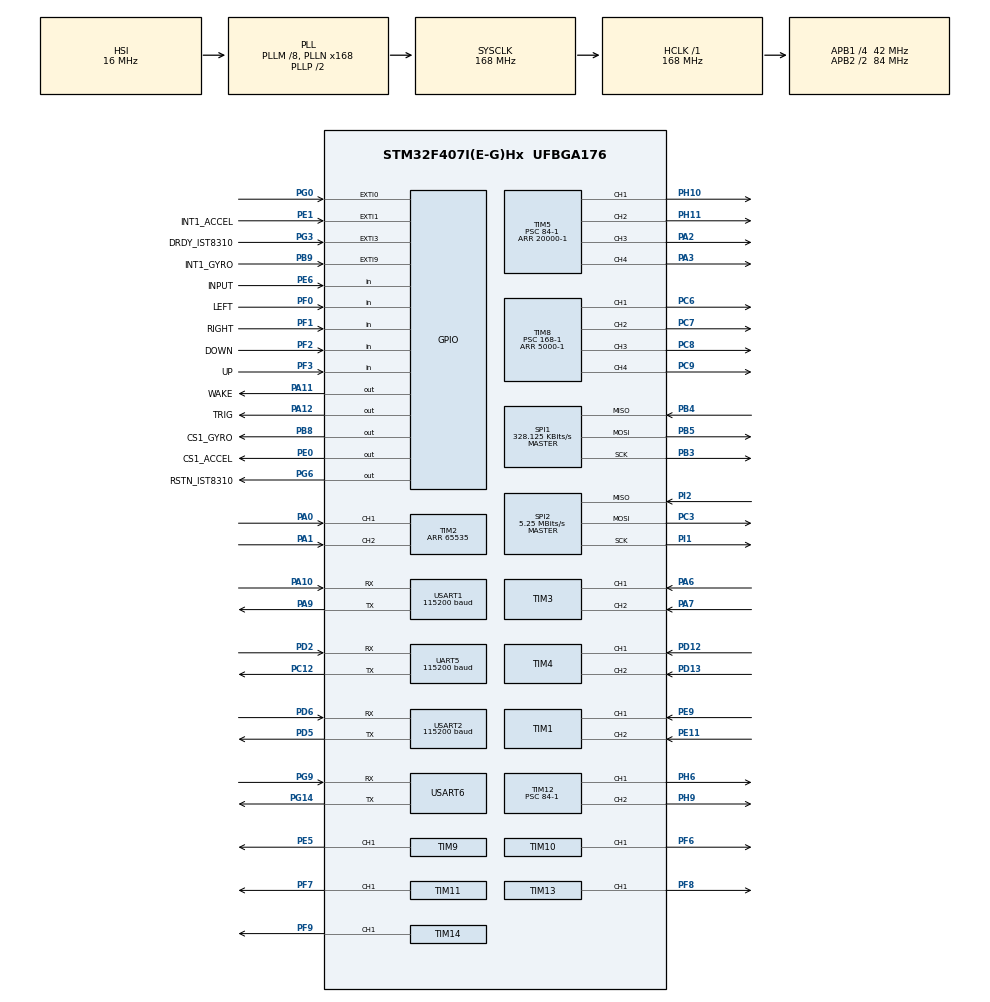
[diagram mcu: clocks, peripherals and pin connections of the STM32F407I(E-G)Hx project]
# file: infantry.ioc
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Dma.Request0=USART1_RX
Dma.Request1=USART6_RX
Dma.Request2=USART6_TX
Dma.Request3=SPI2_TX
Dma.Request4=UART5_TX
Dma.Request5=USART2_RX
Dma.Request6=UART5_RX
Dma.SPI2_TX.3.Direction=DMA_MEMORY_TO_PERIPH
Dma.SPI2_TX.3.FIFOMode=DMA_FIFOMODE_DISABLE
Dma.SPI2_TX.3.Instance=DMA1_Stream4
Dma.SPI2_TX.3.MemDataAlignment=DMA_MDATAALIGN_BYTE
Dma.SPI2_TX.3.MemInc=DMA_MINC_ENABLE
Dma.SPI2_TX.3.Mode=DMA_NORMAL
Dma.SPI2_TX.3.PeriphDataAlignment=DMA_PDATAALIGN_BYTE
Dma.SPI2_TX.3.PeriphInc=DMA_PINC_DISABLE
Dma.SPI2_TX.3.Priority=DMA_PRIORITY_MEDIUM
Dma.UART5_RX.6.Direction=DMA_PERIPH_TO_MEMORY
Dma.UART5_RX.6.FIFOMode=DMA_FIFOMODE_DISABLE
Dma.UART5_RX.6.Instance=DMA1_Stream0
Dma.UART5_RX.6.MemDataAlignment=DMA_MDATAALIGN_BYTE
Dma.UART5_RX.6.MemInc=DMA_MINC_ENABLE
Dma.UART5_RX.6.Mode=DMA_NORMAL
Dma.UART5_RX.6.PeriphDataAlignment=DMA_PDATAALIGN_BYTE
Dma.UART5_RX.6.PeriphInc=DMA_PINC_DISABLE
Dma.UART5_RX.6.Priority=DMA_PRIORITY_HIGH
Dma.UART5_TX.4.Direction=DMA_MEMORY_TO_PERIPH
Dma.UART5_TX.4.FIFOMode=DMA_FIFOMODE_DISABLE
Dma.UART5_TX.4.Instance=DMA1_Stream7
Dma.UART5_TX.4.MemDataAlignment=DMA_MDATAALIGN_BYTE
Dma.UART5_TX.4.MemInc=DMA_MINC_ENABLE
Dma.UART5_TX.4.Mode=DMA_NORMAL
Dma.UART5_TX.4.PeriphDataAlignment=DMA_PDATAALIGN_BYTE
Dma.UART5_TX.4.PeriphInc=DMA_PINC_DISABLE
Dma.UART5_TX.4.Priority=DMA_PRIORITY_LOW
Dma.USART1_RX.0.Direction=DMA_PERIPH_TO_MEMORY
Dma.USART1_RX.0.FIFOMode=DMA_FIFOMODE_DISABLE
Dma.USART1_RX.0.Instance=DMA2_Stream2
Dma.USART1_RX.0.MemDataAlignment=DMA_MDATAALIGN_BYTE
Dma.USART1_RX.0.MemInc=DMA_MINC_ENABLE
Dma.USART1_RX.0.Mode=DMA_NORMAL
Dma.USART1_RX.0.PeriphDataAlignment=DMA_PDATAALIGN_BYTE
Dma.USART1_RX.0.PeriphInc=DMA_PINC_DISABLE
Dma.USART1_RX.0.Priority=DMA_PRIORITY_HIGH
Dma.USART2_RX.5.Direction=DMA_PERIPH_TO_MEMORY
Dma.USART2_RX.5.FIFOMode=DMA_FIFOMODE_DISABLE
Dma.USART2_RX.5.Instance=DMA1_Stream5
Dma.USART2_RX.5.MemDataAlignment=DMA_MDATAALIGN_BYTE
Dma.USART2_RX.5.MemInc=DMA_MINC_ENABLE
Dma.USART2_RX.5.Mode=DMA_NORMAL
Dma.USART2_RX.5.PeriphDataAlignment=DMA_PDATAALIGN_BYTE
Dma.USART2_RX.5.PeriphInc=DMA_PINC_DISABLE
Dma.USART2_RX.5.Priority=DMA_PRIORITY_VERY_HIGH
Dma.USART6_RX.1.Direction=DMA_PERIPH_TO_MEMORY
Dma.USART6_RX.1.FIFOMode=DMA_FIFOMODE_DISABLE
Dma.USART6_RX.1.Instance=DMA2_Stream1
Dma.USART6_RX.1.MemDataAlignment=DMA_MDATAALIGN_BYTE
Dma.USART6_RX.1.MemInc=DMA_MINC_ENABLE
Dma.USART6_RX.1.Mode=DMA_NORMAL
Dma.USART6_RX.1.PeriphDataAlignment=DMA_PDATAALIGN_BYTE
Dma.USART6_RX.1.PeriphInc=DMA_PINC_DISABLE
Dma.USART6_RX.1.Priority=DMA_PRIORITY_HIGH
Dma.USART6_TX.2.Direction=DMA_MEMORY_TO_PERIPH
Dma.USART6_TX.2.FIFOMode=DMA_FIFOMODE_DISABLE
Dma.USART6_TX.2.Instance=DMA2_Stream6
Dma.USART6_TX.2.MemDataAlignment=DMA_MDATAALIGN_BYTE
Dma.USART6_TX.2.MemInc=DMA_MINC_ENABLE
Dma.USART6_TX.2.Mode=DMA_NORMAL
Dma.USART6_TX.2.PeriphDataAlignment=DMA_PDATAALIGN_BYTE
Dma.USART6_TX.2.PeriphInc=DMA_PINC_DISABLE
Dma.USART6_TX.2.Priority=DMA_PRIORITY_MEDIUM
IWDG.Prescaler=IWDG_PRESCALER_128
IWDG.Reload=2000
Mcu.Family=STM32F4
Mcu.Name=STM32F407I(E-G)Hx
Mcu.Package=UFBGA176
NVIC.DMA1_Stream0_IRQn=true\:0\:0\:false\:false\:true\:false\:true\:true
NVIC.DMA1_Stream4_IRQn=true\:1\:0\:true\:false\:true\:false\:true\:true
NVIC.DMA1_Stream5_IRQn=true\:0\:0\:false\:false\:true\:false\:true\:true
NVIC.DMA1_Stream7_IRQn=true\:1\:0\:true\:false\:true\:false\:true\:true
NVIC.DMA2_Stream1_IRQn=true\:0\:0\:false\:false\:true\:false\:true\:true
NVIC.DMA2_Stream2_IRQn=true\:0\:0\:false\:false\:true\:false\:true\:true
NVIC.DMA2_Stream6_IRQn=true\:1\:0\:true\:false\:true\:false\:true\:true
NVIC.EXTI0_IRQn=true\:2\:0\:true\:false\:true\:true\:true\:true
NVIC.EXTI3_IRQn=true\:1\:0\:true\:false\:true\:true\:true\:true
NVIC.EXTI9_5_IRQn=true\:1\:0\:true\:false\:true\:true\:true\:true
NVIC.PriorityGroup=NVIC_PRIORITYGROUP_2
NVIC.TIM6_DAC_IRQn=true\:1\:1\:true\:false\:true\:true\:true\:true
NVIC.TIM7_IRQn=true\:1\:1\:true\:false\:true\:true\:true\:true
NVIC.UART5_IRQn=true\:0\:0\:false\:false\:true\:true\:true\:true
NVIC.USART1_IRQn=true\:0\:0\:false\:false\:true\:true\:true\:true
NVIC.USART2_IRQn=true\:0\:0\:false\:false\:true\:true\:true\:true
PA0-WKUP.Signal=S_TIM2_CH1_ETR
PA1.Signal=S_TIM2_CH2
PA10.Mode=Asynchronous
PA10.Signal=USART1_RX
PA11.GPIO_Label=WAKE
PA11.Signal=GPIO_Output
PA12.GPIO_Label=TRIG 
PA12.GPIO_PuPd=GPIO_PULLUP
PA12.PinState=GPIO_PIN_SET
PA12.Signal=GPIO_Output
PA13.Mode=Serial_Wire
PA13.Signal=SYS_JTMS-SWDIO
PA14.Mode=Serial_Wire
PA14.Signal=SYS_JTCK-SWCLK
PA2.Signal=S_TIM5_CH3
PA3.Signal=S_TIM5_CH4
PA6.Signal=S_TIM3_CH1
PA7.Signal=S_TIM3_CH2
PA9.Mode=Asynchronous
PA9.Signal=USART1_TX
PB3.GPIO_PuPd=GPIO_PULLUP
PB3.Mode=Full_Duplex_Master
PB3.Signal=SPI1_SCK
PB4.GPIO_PuPd=GPIO_PULLUP
PB4.Mode=Full_Duplex_Master
PB4.Signal=SPI1_MISO
PB5.GPIO_PuPd=GPIO_PULLUP
PB5.Mode=Full_Duplex_Master
PB5.Signal=SPI1_MOSI
PB8.GPIO_Label=CS1_GYRO
PB8.GPIO_PuPd=GPIO_PULLUP
PB8.GPIO_Speed=GPIO_SPEED_FREQ_HIGH
PB8.PinState=GPIO_PIN_SET
PB8.Signal=GPIO_Output
PB9.GPIO_Label=INT1_GYRO
PB9.GPIO_ModeDefaultEXTI=GPIO_MODE_IT_FALLING
PB9.GPIO_PuPd=GPIO_PULLUP
PB9.Signal=GPXTI9
PC12.Mode=Asynchronous
PC12.Signal=UART5_TX
PC3.Mode=Full_Duplex_Master
PC3.Signal=SPI2_MOSI
PC6.Signal=S_TIM8_CH1
PC7.Signal=S_TIM8_CH2
PC8.Signal=S_TIM8_CH3
PC9.Signal=S_TIM8_CH4
PD0.GPIO_Label=BoardC_CAN1_Rx
PD0.Signal=CAN1_RX
PD1.GPIO_Label=BoardC_CAN1_Tx
PD1.Signal=CAN1_TX
PD12.Signal=S_TIM4_CH1
PD13.Signal=S_TIM4_CH2
PD2.Mode=Asynchronous
PD2.Signal=UART5_RX
PD5.Mode=Asynchronous
PD5.Signal=USART2_TX
PD6.Mode=Asynchronous
PD6.Signal=USART2_RX
PE0.GPIO_Label=CS1_ACCEL
PE0.GPIO_PuPd=GPIO_PULLUP
PE0.GPIO_Speed=GPIO_SPEED_FREQ_HIGH
PE0.PinState=GPIO_PIN_SET
PE0.Signal=GPIO_Output
PE1.GPIO_Label=INT1_ACCEL
PE1.GPIO_ModeDefaultEXTI=GPIO_MODE_IT_FALLING
PE1.GPIO_PuPd=GPIO_PULLUP
PE1.Signal=GPXTI1
PE11.Signal=S_TIM1_CH2
PE13.Signal=S_TIM1_CH3
PE5.Signal=S_TIM9_CH1
PE6.GPIO_Label=INPUT
PE6.GPIO_PuPd=GPIO_PULLUP
PE6.Signal=GPIO_Input
PE9.Signal=S_TIM1_CH1
PF0.GPIO_Label=LEFT
PF0.GPIO_PuPd=GPIO_PULLUP
PF0.Signal=GPIO_Input
PF1.GPIO_Label=RIGHT
PF1.GPIO_PuPd=GPIO_PULLUP
PF1.Signal=GPIO_Input
PF2.GPIO_Label=DOWN
PF2.GPIO_PuPd=GPIO_PULLUP
PF2.Signal=GPIO_Input
PF3.GPIO_Label=UP
PF3.GPIO_PuPd=GPIO_PULLUP
PF3.Signal=GPIO_Input
PF6.Signal=S_TIM10_CH1
PF7.Signal=S_TIM11_CH1
PF8.Signal=S_TIM13_CH1
PF9.Signal=S_TIM14_CH1
PG0.GPIO_ModeDefaultEXTI=GPIO_MODE_IT_FALLING
PG0.GPIO_PuPd=GPIO_PULLUP
PG0.Signal=GPXTI0
PG14.Mode=Asynchronous
PG14.Signal=USART6_TX
PG3.GPIO_Label=DRDY_IST8310
PG3.GPIO_ModeDefaultEXTI=GPIO_MODE_IT_FALLING
PG3.GPIO_PuPd=GPIO_PULLUP
PG3.Signal=GPXTI3
PG6.GPIO_Label=RSTN_IST8310
PG6.GPIO_PuPd=GPIO_PULLUP
PG6.GPIO_Speed=GPIO_SPEED_FREQ_MEDIUM
PG6.PinState=GPIO_PIN_SET
PG6.Signal=GPIO_Output
PG9.Mode=Asynchronous
PG9.Signal=USART6_RX
PH0-OSC_IN.Mode=HSE-External-Oscillator
PH0-OSC_IN.Signal=RCC_OSC_IN
PH1-OSC_OUT.Mode=HSE-External-Oscillator
PH1-OSC_OUT.Signal=RCC_OSC_OUT
PH10.Signal=S_TIM5_CH1
PH11.Signal=S_TIM5_CH2
PH6.Signal=S_TIM12_CH1
PH9.Signal=S_TIM12_CH2
PI1.Mode=Full_Duplex_Master
PI1.Signal=SPI2_SCK
PI2.Mode=Full_Duplex_Master
PI2.Signal=SPI2_MISO
ProjectManager.HeapSize=0xf00
ProjectManager.StackSize=0xf00
ProjectManager.TargetToolchain=MDK-ARM V5.32
RCC.48MHZClocksFreq_Value=48000000
RCC.AHBFreq_Value=168000000
RCC.APB1CLKDivider=RCC_HCLK_DIV4
RCC.APB1Freq_Value=42000000
RCC.APB1TimFreq_Value=84000000
RCC.APB2CLKDivider=RCC_HCLK_DIV2
RCC.APB2Freq_Value=84000000
RCC.APB2TimFreq_Value=168000000
RCC.CortexFreq_Value=168000000
RCC.HCLKFreq_Value=168000000
RCC.HSE_VALUE=16000000
RCC.HSI_VALUE=16000000
RCC.LSE_VALUE=32768
RCC.PLLM=8
RCC.PLLN=168
RCC.PLLQ=7
RCC.SYSCLKFreq_VALUE=168000000
RCC.SYSCLKSource=RCC_SYSCLKSOURCE_PLLCLK
RCC.VCOOutputFreq_Value=336000000
SH.S_TIM10_CH1.0=TIM10_CH1,PWM Generation1 CH1
SH.S_TIM11_CH1.0=TIM11_CH1,PWM Generation1 CH1
SH.S_TIM12_CH1.0=TIM12_CH1,PWM Generation1 CH1
SH.S_TIM12_CH2.0=TIM12_CH2,PWM Generation2 CH2
SH.S_TIM13_CH1.0=TIM13_CH1,PWM Generation1 CH1
SH.S_TIM14_CH1.0=TIM14_CH1,PWM Generation1 CH1
SH.S_TIM1_CH1.0=TIM1_CH1,Encoder_Interface
SH.S_TIM1_CH2.0=TIM1_CH2,Encoder_Interface
SH.S_TIM1_CH3.0=TIM1_CH3
SH.S_TIM2_CH1_ETR.0=TIM2_CH1,Encoder_Interface
SH.S_TIM2_CH2.0=TIM2_CH2,Encoder_Interface
SH.S_TIM3_CH1.0=TIM3_CH1,Encoder_Interface
SH.S_TIM3_CH2.0=TIM3_CH2,Encoder_Interface
SH.S_TIM4_CH1.0=TIM4_CH1,Encoder_Interface
SH.S_TIM4_CH2.0=TIM4_CH2,Encoder_Interface
SH.S_TIM5_CH1.0=TIM5_CH1,PWM Generation1 CH1
SH.S_TIM5_CH2.0=TIM5_CH2,PWM Generation2 CH2
SH.S_TIM5_CH3.0=TIM5_CH3,PWM Generation3 CH3
SH.S_TIM5_CH4.0=TIM5_CH4,PWM Generation4 CH4
SH.S_TIM8_CH1.0=TIM8_CH1,PWM Generation1 CH1
SH.S_TIM8_CH2.0=TIM8_CH2,PWM Generation2 CH2
SH.S_TIM8_CH3.0=TIM8_CH3,PWM Generation3 CH3
SH.S_TIM8_CH4.0=TIM8_CH4,PWM Generation4 CH4
SH.S_TIM9_CH1.0=TIM9_CH1,PWM Generation1 CH1
SPI1.BaudRatePrescaler=SPI_BAUDRATEPRESCALER_256
SPI1.CLKPhase=SPI_PHASE_2EDGE
SPI1.CLKPolarity=SPI_POLARITY_HIGH
SPI1.CalculateBaudRate=328.125 KBits/s
SPI1.Direction=SPI_DIRECTION_2LINES
SPI1.Mode=SPI_MODE_MASTER
SPI1.VirtualType=VM_MASTER
SPI2.BaudRatePrescaler=SPI_BAUDRATEPRESCALER_8
SPI2.CLKPhase=SPI_PHASE_2EDGE
SPI2.CalculateBaudRate=5.25 MBits/s
SPI2.Direction=SPI_DIRECTION_2LINES
SPI2.Mode=SPI_MODE_MASTER
SPI2.VirtualType=VM_MASTER
TIM1.EncoderMode=TIM_ENCODERMODE_TI12
TIM10.AutoReloadPreload=TIM_AUTORELOAD_PRELOAD_ENABLE
TIM10.Channel=TIM_CHANNEL_1
TIM10.Period=20000-1
TIM10.Prescaler=168-1
TIM11.AutoReloadPreload=TIM_AUTORELOAD_PRELOAD_ENABLE
TIM11.Channel=TIM_CHANNEL_1
TIM11.Period=20000-1
TIM11.Prescaler=168-1
TIM12.Channel-PWM\ Generation1\ CH1=TIM_CHANNEL_1
TIM12.Channel-PWM\ Generation2\ CH2=TIM_CHANNEL_2
TIM12.Period=5000-1
TIM12.Prescaler=84-1
TIM13.AutoReloadPreload=TIM_AUTORELOAD_PRELOAD_ENABLE
TIM13.Channel=TIM_CHANNEL_1
TIM13.Period=20000-1
TIM13.Prescaler=84-1
TIM14.AutoReloadPreload=TIM_AUTORELOAD_PRELOAD_ENABLE
TIM14.Channel=TIM_CHANNEL_1
TIM14.Period=20000-1
TIM14.Prescaler=84-1
TIM2.EncoderMode=TIM_ENCODERMODE_TI12
TIM2.Period=65535
TIM3.EncoderMode=TIM_ENCODERMODE_TI12
TIM4.EncoderMode=TIM_ENCODERMODE_TI12
TIM5.AutoReloadPreload=TIM_AUTORELOAD_PRELOAD_ENABLE
TIM5.Channel-PWM\ Generation1\ CH1=TIM_CHANNEL_1
TIM5.Channel-PWM\ Generation2\ CH2=TIM_CHANNEL_2
TIM5.Channel-PWM\ Generation3\ CH3=TIM_CHANNEL_3
TIM5.Channel-PWM\ Generation4\ CH4=TIM_CHANNEL_4
TIM5.Period=20000-1
TIM5.Prescaler=84-1
TIM6.Period=1000-1
TIM6.Prescaler=84-1
TIM7.Period=5000-1
TIM7.Prescaler=84-1
TIM8.Channel-PWM\ Generation1\ CH1=TIM_CHANNEL_1
TIM8.Channel-PWM\ Generation2\ CH2=TIM_CHANNEL_2
TIM8.Channel-PWM\ Generation3\ CH3=TIM_CHANNEL_3
TIM8.Channel-PWM\ Generation4\ CH4=TIM_CHANNEL_4
TIM8.Period=5000-1
TIM8.Prescaler=168-1
TIM9.Channel-PWM\ Generation1\ CH1=TIM_CHANNEL_1
TIM9.Period=5000-1
TIM9.Prescaler=0
UART5.BaudRate=115200
UART5.VirtualMode=Asynchronous
USART1.BaudRate=115200
USART1.VirtualMode=VM_ASYNC
USART2.BaudRate=115200
USART2.VirtualMode=VM_ASYNC
USART6.VirtualMode=VM_ASYNC
VP_IWDG_VS_IWDG.Mode=IWDG_Activate
VP_TIM10_VS_ClockSourceINT.Mode=Enable_Timer
VP_TIM11_VS_ClockSourceINT.Mode=Enable_Timer
VP_TIM12_VS_ClockSourceINT.Mode=Internal
VP_TIM13_VS_ClockSourceINT.Mode=Enable_Timer
VP_TIM14_VS_ClockSourceINT.Mode=Enable_Timer
VP_TIM5_VS_ClockSourceINT.Mode=Internal
VP_TIM6_VS_ClockSourceINT.Mode=Enable_Timer
VP_TIM7_VS_ClockSourceINT.Mode=Enable_Timer
VP_TIM8_VS_ClockSourceINT.Mode=Internal
VP_TIM9_VS_ClockSourceINT.Mode=Internal
board=custom

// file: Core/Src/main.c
/* USER CODE BEGIN Header */
/**
  ******************************************************************************
  * @file           : main.c
  * @brief          : Main program body
  ******************************************************************************
  * @attention
  *
  * Copyright (c) 2024 STMicroelectronics.
  * All rights reserved.
  *
  * This software is licensed under terms that can be found in the LICENSE file
  * in the root directory of this software component.
  * If no LICENSE file comes with this software, it is provided AS-IS.
  *
  ******************************************************************************
  */
/* USER CODE END Header */
#include "main.h"
#include "dma.h"
#include "iwdg.h"
#include "spi.h"
#include "tim.h"
#include "usart.h"
#include "gpio.h"

/* USER CODE BEGIN Includes */
#include "tsk_config_and_callback.h"

/* USER CODE END Includes */

void SystemClock_Config(void);

int main(void)
{

  /* MCU Configuration--------------------------------------------------------*/

  /* Reset of all peripherals, Initializes the Flash interface and the Systick. */
  HAL_Init();

  /* Configure the system clock */
  SystemClock_Config();

  /* Initialize all configured peripherals */
  MX_GPIO_Init();
  MX_DMA_Init();
  MX_TIM3_Init();
  MX_TIM4_Init();
  MX_TIM5_Init();
  MX_TIM1_Init();
  MX_TIM2_Init();
  MX_TIM6_Init();
  MX_TIM7_Init();
  MX_TIM8_Init();
  MX_TIM9_Init();
  MX_TIM12_Init();
  MX_TIM13_Init();
  MX_TIM14_Init();
  MX_USART2_UART_Init();
  MX_USART1_UART_Init();
  MX_SPI2_Init();
  MX_UART5_Init();
  MX_USART6_UART_Init();
  MX_SPI1_Init();
  MX_IWDG_Init();
  MX_TIM11_Init();
  MX_TIM10_Init();
  /* USER CODE BEGIN 2 */
  Task_Init();
  /* USER CODE END 2 */

  /* Infinite loop */
  /* USER CODE BEGIN WHILE */
  while (1)
  {
    //看门�?2s喂狗
    Task_Loop();
    /* USER CODE END WHILE */

  }
}

void SystemClock_Config(void)
{
  RCC_OscInitTypeDef RCC_OscInitStruct = {0};
  RCC_ClkInitTypeDef RCC_ClkInitStruct = {0};

  /** Configure the main internal regulator output voltage
  */
  __HAL_RCC_PWR_CLK_ENABLE();
  __HAL_PWR_VOLTAGESCALING_CONFIG(PWR_REGULATOR_VOLTAGE_SCALE1);

  /** Initializes the RCC Oscillators according to the specified parameters
  * in the RCC_OscInitTypeDef structure.
  */
  RCC_OscInitStruct.OscillatorType = RCC_OSCILLATORTYPE_HSI|RCC_OSCILLATORTYPE_LSI;
  RCC_OscInitStruct.HSIState = RCC_HSI_ON;
  RCC_OscInitStruct.HSICalibrationValue = RCC_HSICALIBRATION_DEFAULT;
  RCC_OscInitStruct.LSIState = RCC_LSI_ON;
  RCC_OscInitStruct.PLL.PLLState = RCC_PLL_ON;
  RCC_OscInitStruct.PLL.PLLSource = RCC_PLLSOURCE_HSI;
  RCC_OscInitStruct.PLL.PLLM = 8;
  RCC_OscInitStruct.PLL.PLLN = 168;
  RCC_OscInitStruct.PLL.PLLP = RCC_PLLP_DIV2;
  RCC_OscInitStruct.PLL.PLLQ = 7;
  if (HAL_RCC_OscConfig(&RCC_OscInitStruct) != HAL_OK)
  {
    Error_Handler();
  }

  /** Initializes the CPU, AHB and APB buses clocks
  */
  RCC_ClkInitStruct.ClockType = RCC_CLOCKTYPE_HCLK|RCC_CLOCKTYPE_SYSCLK
                              |RCC_CLOCKTYPE_PCLK1|RCC_CLOCKTYPE_PCLK2;
  RCC_ClkInitStruct.SYSCLKSource = RCC_SYSCLKSOURCE_PLLCLK;
  RCC_ClkInitStruct.AHBCLKDivider = RCC_SYSCLK_DIV1;
  RCC_ClkInitStruct.APB1CLKDivider = RCC_HCLK_DIV4;
  RCC_ClkInitStruct.APB2CLKDivider = RCC_HCLK_DIV2;

  if (HAL_RCC_ClockConfig(&RCC_ClkInitStruct, FLASH_LATENCY_5) != HAL_OK)
  {
    Error_Handler();
  }
}

void Error_Handler(void)
{
  __disable_irq();
  while (1)
  {
  }
}
